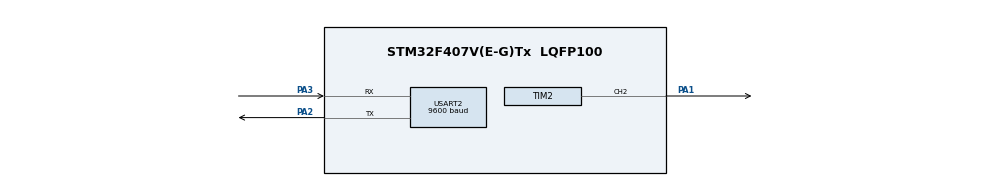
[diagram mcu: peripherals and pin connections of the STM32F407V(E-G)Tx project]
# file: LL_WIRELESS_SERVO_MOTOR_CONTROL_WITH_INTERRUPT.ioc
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Mcu.Family=STM32F4
Mcu.Name=STM32F407V(E-G)Tx
Mcu.Package=LQFP100
NVIC.PriorityGroup=NVIC_PRIORITYGROUP_4
NVIC.USART2_IRQn=true\:0\:0\:false\:false\:true\:true\:true\:true
PA1.Signal=S_TIM2_CH2
PA2.Mode=Asynchronous
PA2.Signal=USART2_TX
PA3.Mode=Asynchronous
PA3.Signal=USART2_RX
PH0-OSC_IN.Mode=HSE-External-Oscillator
PH0-OSC_IN.Signal=RCC_OSC_IN
PH1-OSC_OUT.Mode=HSE-External-Oscillator
PH1-OSC_OUT.Signal=RCC_OSC_OUT
ProjectManager.HeapSize=0x200
ProjectManager.StackSize=0x400
ProjectManager.TargetToolchain=STM32CubeIDE
RCC.48MHZClocksFreq_Value=84000000
RCC.AHBFreq_Value=168000000
RCC.APB1CLKDivider=RCC_HCLK_DIV4
RCC.APB1Freq_Value=42000000
RCC.APB1TimFreq_Value=84000000
RCC.APB2CLKDivider=RCC_HCLK_DIV2
RCC.APB2Freq_Value=84000000
RCC.APB2TimFreq_Value=168000000
RCC.CortexFreq_Value=168000000
RCC.HCLKFreq_Value=168000000
RCC.HSE_VALUE=8000000
RCC.HSI_VALUE=16000000
RCC.LSE_VALUE=32768
RCC.PLLM=4
RCC.PLLN=168
RCC.PLLSourceVirtual=RCC_PLLSOURCE_HSE
RCC.SYSCLKFreq_VALUE=168000000
RCC.SYSCLKSource=RCC_SYSCLKSOURCE_PLLCLK
RCC.VCOOutputFreq_Value=336000000
SH.S_TIM2_CH2.0=TIM2_CH2,PWM Generation2 CH2
TIM2.Channel-PWM\ Generation2\ CH2=TIM_CHANNEL_2
TIM2.Period=19999
TIM2.Prescaler=83
USART2.BaudRate=9600
USART2.VirtualMode=VM_ASYNC
board=custom

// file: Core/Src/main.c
/* USER CODE BEGIN Header */
/**
  ******************************************************************************
  * @file           : main.c
  * @brief          : Main program body
  ******************************************************************************
  * @attention
  *
  * Copyright (c) 2024 STMicroelectronics.
  * All rights reserved.
  *
  * This software is licensed under terms that can be found in the LICENSE file
  * in the root directory of this software component.
  * If no LICENSE file comes with this software, it is provided AS-IS.
  *
  ******************************************************************************
  */
/* USER CODE END Header */
#include "main.h"

/* USER CODE BEGIN Includes */
#include <stdio.h>
#include <string.h>
#include <stdlib.h>
/* USER CODE END Includes */

/* USER CODE BEGIN PV */
char tx_buffer[50], rx_buffer[50];
int  rx_index;
uint8_t data, angle;
uint16_t pulse;

/* USER CODE END PV */

void SystemClock_Config(void);
static void MX_GPIO_Init(void);
static void MX_TIM2_Init(void);
static void MX_USART2_UART_Init(void);

/* USER CODE BEGIN 0 */

/**
  * @brief  Maps the input value from one range to another.
  * @param  in_value: Input value to be mapped.
  * @param  in_min: Minimum value of the input range.
  * @param  in_max: Maximum value of the input range.
  * @param  out_min: Minimum value of the output range.
  * @param  out_max: Maximum value of the output range.
  * @retval Mapped output value.
  */
uint16_t map_value(uint8_t in_value, uint8_t in_min, uint8_t in_max, uint16_t out_min, uint16_t out_max)
{
    return out_min + ((in_value - in_min) * (out_max - out_min)) / (in_max - in_min);
}

/**
  * @brief  Sends a string over USART.
  * @param  USARTx: USART instance to use.
  * @param  str: Pointer to the string to be sent.
  * @retval None
  */
void USART_Send_String(USART_TypeDef *USARTx, char *str)
{
    while (*str)
    {
        // Wait for the transmit data register to be empty
        while(!LL_USART_IsActiveFlag_TXE(USARTx));

        // Send the data
        LL_USART_TransmitData8(USARTx, *str++);

        // Wait for the transmission to complete if needed
        // while(!LL_USART_IsActiveFlag_TC(USARTx));
    }

    // Wait for the last byte to be transmitted
    while(!LL_USART_IsActiveFlag_TC(USARTx));
}

/**
  * @brief  USART2 IRQ handler.
  * @retval None
  */
void USART2_IRQHandler(void)
{
    // Check if the RXNE flag is set
    if (LL_USART_IsActiveFlag_RXNE(USART2))
    {
        data = LL_USART_ReceiveData8(USART2);

        if (data == '\r')
        {
            // Handle carriage return if needed
        }
        else if(data == '\n') //the app i used sends '\r' then sends 'n' after the data by user is sent
        {
            rx_buffer[rx_index] = '\0';
            switch (rx_index)
            {
                case 1:
                    angle = (rx_buffer[0] - '0');
                    break;
                case 2:
                    angle = (rx_buffer[0] - '0') * 10 + (rx_buffer[1] - '0');
                    break;
                case 3:
                    angle = (rx_buffer[0] - '0') * 100 + (rx_buffer[1] - '0') * 10 + (rx_buffer[2] - '0');
                    break;
            }
            pulse = map_value(angle, 0, 180, 499, 2499);
            LL_TIM_OC_SetCompareCH2(TIM2, pulse);

            sprintf(tx_buffer, "The angle is %u", angle);
            USART_Send_String(USART2, tx_buffer);
            rx_index = 0;
        }
        else
        {
            if (rx_index < sizeof(rx_buffer) - 1) // Buffer overflow check
            {
                rx_buffer[rx_index++] = data;
            }
        }
    }
}

/* USER CODE END 0 */

int main(void)
{

    /* MCU Configuration--------------------------------------------------------*/

    /* Reset of all peripherals, Initializes the Flash interface and the Systick. */
    LL_APB2_GRP1_EnableClock(LL_APB2_GRP1_PERIPH_SYSCFG);
    LL_APB1_GRP1_EnableClock(LL_APB1_GRP1_PERIPH_PWR);

    /* System interrupt init*/
    NVIC_SetPriorityGrouping(NVIC_PRIORITYGROUP_4);

    /* SysTick_IRQn interrupt configuration */
    NVIC_SetPriority(SysTick_IRQn, NVIC_EncodePriority(NVIC_GetPriorityGrouping(), 15, 0));

    /* Configure the system clock */
    SystemClock_Config();

    /* Initialize all configured peripherals */
    MX_GPIO_Init();
    MX_TIM2_Init();
    MX_USART2_UART_Init();

    /* USER CODE BEGIN 2 */
    USART_Send_String(USART2, "Please enter the angle value\n");

    // Start TIM2 counter and enable PWM output
    LL_TIM_EnableCounter(TIM2);
    LL_TIM_EnableAllOutputs(TIM2);

    // Enable TIM2 channel 2 for PWM output
    LL_TIM_CC_EnableChannel(TIM2, LL_TIM_CHANNEL_CH2);

    /* USER CODE END 2 */

    /* Infinite loop */
    while (1)
    {

    }
}

void SystemClock_Config(void)
{
    LL_FLASH_SetLatency(LL_FLASH_LATENCY_5);
    while(LL_FLASH_GetLatency() != LL_FLASH_LATENCY_5)
    {
    }
    LL_PWR_SetRegulVoltageScaling(LL_PWR_REGU_VOLTAGE_SCALE1);
    LL_RCC_HSE_Enable();

    /* Wait till HSE is ready */
    while(LL_RCC_HSE_IsReady() != 1)
    {
    }
    LL_RCC_PLL_ConfigDomain_SYS(LL_RCC_PLLSOURCE_HSE, LL_RCC_PLLM_DIV_4, 168, LL_RCC_PLLP_DIV_2);
    LL_RCC_PLL_Enable();

    /* Wait till PLL is ready */
    while(LL_RCC_PLL_IsReady() != 1)
    {
    }
    while (LL_PWR_IsActiveFlag_VOS() == 0)
    {
    }
    LL_RCC_SetAHBPrescaler(LL_RCC_SYSCLK_DIV_1);
    LL_RCC_SetAPB1Prescaler(LL_RCC_APB1_DIV_4);
    LL_RCC_SetAPB2Prescaler(LL_RCC_APB2_DIV_2);
    LL_RCC_SetSysClkSource(LL_RCC_SYS_CLKSOURCE_PLL);

    /* Wait till System clock is ready */
    while(LL_RCC_GetSysClkSource() != LL_RCC_SYS_CLKSOURCE_STATUS_PLL)
    {
    }
    LL_Init1msTick(168000000);
    LL_SetSystemCoreClock(168000000);
}

static void MX_TIM2_Init(void)
{

    LL_TIM_InitTypeDef TIM_InitStruct = {0};
    LL_TIM_OC_InitTypeDef TIM_OC_InitStruct = {0};

    LL_GPIO_InitTypeDef GPIO_InitStruct = {0};

    /* Peripheral clock enable */
    LL_APB1_GRP1_EnableClock(LL_APB1_GRP1_PERIPH_TIM2);

    TIM_InitStruct.Prescaler = 83;
    TIM_InitStruct.CounterMode = LL_TIM_COUNTERMODE_UP;
    TIM_InitStruct.Autoreload = 19999;
    TIM_InitStruct.ClockDivision = LL_TIM_CLOCKDIVISION_DIV1;
    LL_TIM_Init(TIM2, &TIM_InitStruct);
    LL_TIM_DisableARRPreload(TIM2);
    LL_TIM_OC_EnablePreload(TIM2, LL_TIM_CHANNEL_CH2);
    TIM_OC_InitStruct.OCMode = LL_TIM_OCMODE_PWM1;
    TIM_OC_InitStruct.OCState = LL_TIM_OCSTATE_DISABLE;
    TIM_OC_InitStruct.OCNState = LL_TIM_OCSTATE_DISABLE;
    TIM_OC_InitStruct.CompareValue = 0;
    TIM_OC_InitStruct.OCPolarity = LL_TIM_OCPOLARITY_HIGH;
    LL_TIM_OC_Init(TIM2, LL_TIM_CHANNEL_CH2, &TIM_OC_InitStruct);
    LL_TIM_OC_DisableFast(TIM2, LL_TIM_CHANNEL_CH2);
    LL_TIM_SetTriggerOutput(TIM2, LL_TIM_TRGO_RESET);
    LL_TIM_DisableMasterSlaveMode(TIM2);
    LL_AHB1_GRP1_EnableClock(LL_AHB1_GRP1_PERIPH_GPIOA);
    /**TIM2 GPIO Configuration
    PA1   ------> TIM2_CH2
    */
    GPIO_InitStruct.Pin = LL_GPIO_PIN_1;
    GPIO_InitStruct.Mode = LL_GPIO_MODE_ALTERNATE;
    GPIO_InitStruct.Speed = LL_GPIO_SPEED_FREQ_LOW;
    GPIO_InitStruct.OutputType = LL_GPIO_OUTPUT_PUSHPULL;
    GPIO_InitStruct.Pull = LL_GPIO_PULL_NO;
    GPIO_InitStruct.Alternate = LL_GPIO_AF_1;
    LL_GPIO_Init(GPIOA, &GPIO_InitStruct);
}

static void MX_USART2_UART_Init(void)
{

    LL_USART_InitTypeDef USART_InitStruct = {0};

    LL_GPIO_InitTypeDef GPIO_InitStruct = {0};

    /* Peripheral clock enable */
    LL_APB1_GRP1_EnableClock(LL_APB1_GRP1_PERIPH_USART2);

    LL_AHB1_GRP1_EnableClock(LL_AHB1_GRP1_PERIPH_GPIOA);
    /**USART2 GPIO Configuration
    PA2   ------> USART2_TX
    PA3   ------> USART2_RX
    */
    GPIO_InitStruct.Pin = LL_GPIO_PIN_2|LL_GPIO_PIN_3;
    GPIO_InitStruct.Mode = LL_GPIO_MODE_ALTERNATE;
    GPIO_InitStruct.Speed = LL_GPIO_SPEED_FREQ_VERY_HIGH;
    GPIO_InitStruct.OutputType = LL_GPIO_OUTPUT_PUSHPULL;
    GPIO_InitStruct.Pull = LL_GPIO_PULL_NO;
    GPIO_InitStruct.Alternate = LL_GPIO_AF_7;
    LL_GPIO_Init(GPIOA, &GPIO_InitStruct);

    /* USART2 interrupt Init */
    NVIC_SetPriority(USART2_IRQn, NVIC_EncodePriority(NVIC_GetPriorityGrouping(), 0, 0));
    NVIC_EnableIRQ(USART2_IRQn);

    USART_InitStruct.BaudRate = 9600;
    USART_InitStruct.DataWidth = LL_USART_DATAWIDTH_8B;
    USART_InitStruct.StopBits = LL_USART_STOPBITS_1;
    USART_InitStruct.Parity = LL_USART_PARITY_NONE;
    USART_InitStruct.TransferDirection = LL_USART_DIRECTION_TX_RX;
    USART_InitStruct.HardwareFlowControl = LL_USART_HWCONTROL_NONE;
    USART_InitStruct.OverSampling = LL_USART_OVERSAMPLING_16;
    LL_USART_Init(USART2, &USART_InitStruct);
    LL_USART_ConfigAsyncMode(USART2);
    LL_USART_Enable(USART2);
    /* USER CODE BEGIN USART2_Init 2 */
    LL_USART_EnableIT_RXNE(USART2);
    /* USER CODE END USART2_Init 2 */
}

static void MX_GPIO_Init(void)
{

    /* GPIO Ports Clock Enable */
    LL_AHB1_GRP1_EnableClock(LL_AHB1_GRP1_PERIPH_GPIOH);
    LL_AHB1_GRP1_EnableClock(LL_AHB1_GRP1_PERIPH_GPIOA);

}

void Error_Handler(void)
{
    __disable_irq();
    while (1)
    {
    }
}

#ifdef  USE_FULL_ASSERT
/**
  * @brief  Reports the name of the source file and the source line number
  *         where the assert_param error has occurred.
  * @param  file: pointer to the source file name
  * @param  line: assert_param error line source number
  * @retval None
  */
void assert_failed(uint8_t *file, uint32_t line)
{
    /* USER CODE BEGIN 6 */
    /* User can add his own implementation to report the file name and line number,
       e.g., printf("Wrong parameters value: file %s on line %d\r\n", file, line) */
    /* USER CODE END 6 */
}
#endif /* USE_FULL_ASSERT */
